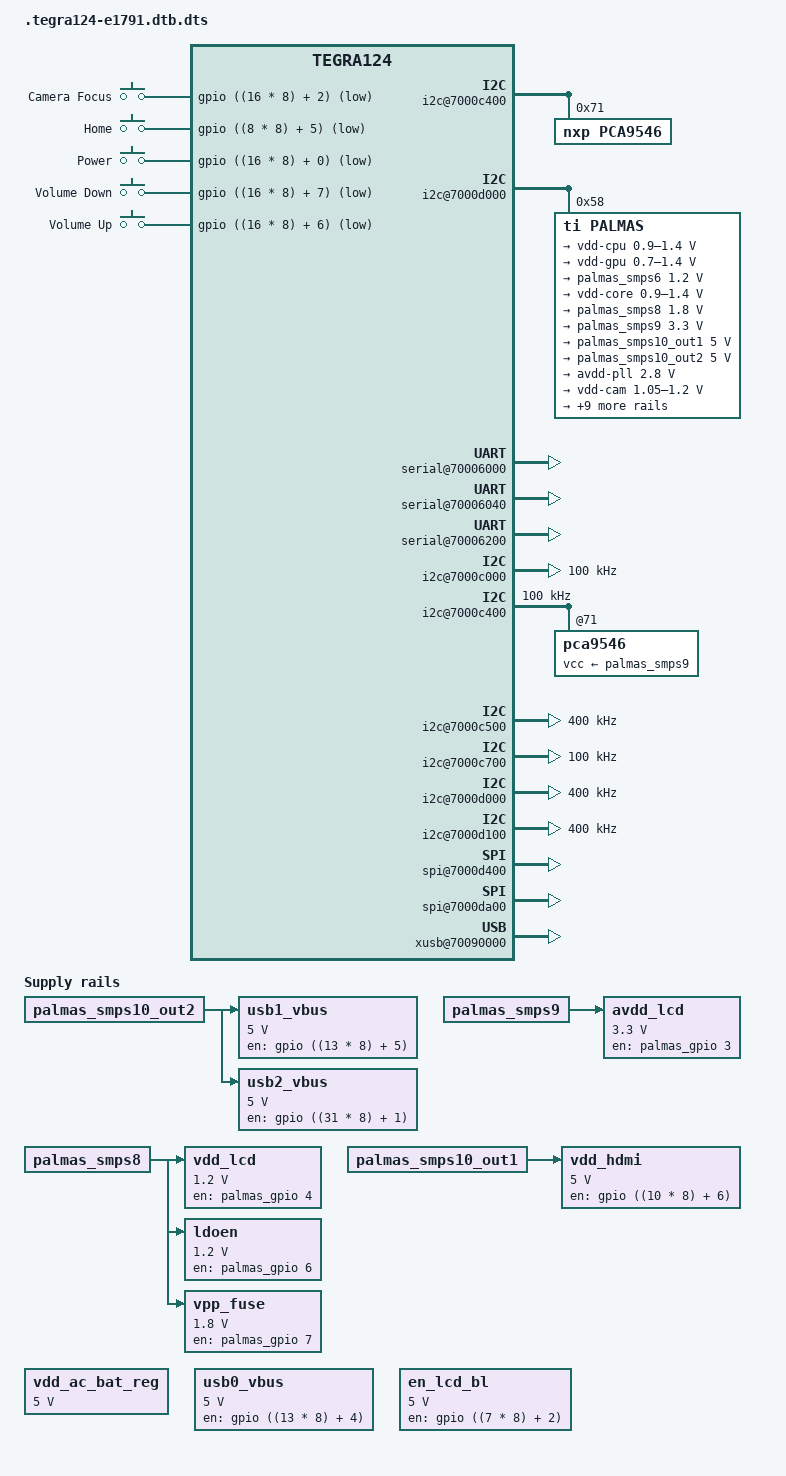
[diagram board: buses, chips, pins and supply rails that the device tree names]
# 1 "arch/arm/boot/dts/tegra124-e1791.dts"
# 1 "<built-in>"
# 1 "<command-line>"
# 1 "arch/arm/boot/dts/tegra124-e1791.dts"
/dts-v1/;

# 1 "arch/arm/boot/dts/tegra124.dtsi" 1
# 1 "/home/leeymcj/linuxrk-tk1/arch/arm/boot/dts/include/dt-bindings/gpio/tegra-gpio.h" 1
# 13 "/home/leeymcj/linuxrk-tk1/arch/arm/boot/dts/include/dt-bindings/gpio/tegra-gpio.h"
# 1 "/home/leeymcj/linuxrk-tk1/arch/arm/boot/dts/include/dt-bindings/gpio/gpio.h" 1
# 14 "/home/leeymcj/linuxrk-tk1/arch/arm/boot/dts/include/dt-bindings/gpio/tegra-gpio.h" 2
# 2 "arch/arm/boot/dts/tegra124.dtsi" 2
# 1 "/home/leeymcj/linuxrk-tk1/arch/arm/boot/dts/include/dt-bindings/input/input.h" 1
# 3 "arch/arm/boot/dts/tegra124.dtsi" 2
# 1 "/home/leeymcj/linuxrk-tk1/arch/arm/boot/dts/include/dt-bindings/interrupt-controller/arm-gic.h" 1







# 1 "/home/leeymcj/linuxrk-tk1/arch/arm/boot/dts/include/dt-bindings/interrupt-controller/irq.h" 1
# 9 "/home/leeymcj/linuxrk-tk1/arch/arm/boot/dts/include/dt-bindings/interrupt-controller/arm-gic.h" 2
# 4 "arch/arm/boot/dts/tegra124.dtsi" 2

/include/ "tegra124-soc.dtsi"

# 1 "arch/arm/boot/dts/skeleton.dtsi" 1






/ {
 #address-cells = <1>;
 #size-cells = <1>;
 chosen { };
 aliases { };
 memory { device_type = "memory"; reg = <0 0>; };
};
# 8 "arch/arm/boot/dts/tegra124.dtsi" 2

/ {
 compatible = "nvidia,tegra124";
 interrupt-parent = <&intc>;
 #address-cells = <1>;
 #size-cells = <1>;

 intc: interrupt-controller@50041000 {
  compatible = "arm,cortex-a15-gic";
  interrupt-controller;
  #interrupt-cells = <3>;
  reg = <0x50041000 0x1000>,
        <0x50042000 0x0100>;
 };

 lic: interrupt-controller@60004000 {
  compatible = "nvidia,tegra-gic";
  interrupt-controller;
  reg = <0x60004000 0x40>,
        <0x60004100 0x40>,
        <0x60004200 0x40>,
        <0x60004300 0x40>,
        <0x60004400 0x40>;
        };

 timer {
  compatible = "arm,armv7-timer";
  interrupts = <1 13 0xf04
         1 14 0xf04>;
 };
};
# 4 "arch/arm/boot/dts/tegra124-e1791.dts" 2
# 1 "arch/arm/boot/dts/tegra124-platforms/tegra124-e1780-powermon.dtsi" 1
# 18 "arch/arm/boot/dts/tegra124-platforms/tegra124-e1780-powermon.dtsi"
/ {
 aliases {
  i2c6 = &pca9546_i2c0;
  i2c7 = &pca9546_i2c1;
  i2c8 = &pca9546_i2c2;
  i2c9 = &pca9546_i2c3;
 };

 i2c@7000c400 {
  pca9546@71 {
   compatible = "nxp,pca9546";
   reg = <0x71>;
   #address-cells = <1>;
   #size-cells = <0>;
   pca9546_i2c0: i2c@0 {
    reg = <0>;
    i2c-mux,deselect-on-exit;
   };

   pca9546_i2c1: i2c@1 {
    reg = <1>;
    i2c-mux,deselect-on-exit;
   };

   pca9546_i2c2: i2c@2 {
    reg = <2>;
    i2c-mux,deselect-on-exit;
   };

   pca9546_i2c3: i2c@3 {
    reg = <3>;
    i2c-mux,deselect-on-exit;
   };
  };
 };
};
# 5 "arch/arm/boot/dts/tegra124-e1791.dts" 2
# 1 "arch/arm/boot/dts/tegra124-platforms/tegra124-e1791-e1736-pmic.dtsi" 1
/ {
 i2c@7000d000 {
  palmas: tps65913 {
   compatible = "ti,palmas";
   reg = <0x58>;
   interrupts = <0 86 0>;

   #interrupt-cells = <2>;
   interrupt-controller;

   palmas_gpio: gpio {
    compatible = "ti,palmas-gpio";
    gpio-controller;
    #gpio-cells = <2>;
   };

   rtc {
    compatible = "ti,palmas-rtc";
    interrupt-parent = <&palmas>;
    interrupts = <8 0>;
   };

   pinmux {
    compatible = "ti,tps65913-pinctrl";
    pinctrl-names = "default";
    pinctrl-0 = <&palmas_default>;

    palmas_default: pinmux {
     powergood {
      pins = "powergood";
      function = "powergood";
     };

     vac {
      pins = "vac";
      function = "vac";
     };

     pin_gpio0 {
      pins = "gpio0";
      function = "id";
      bias-pull-up;
     };

     pin_gpio1 {
      pins = "gpio1";
      function = "vbus_det";
     };

     pin_gpio6 {
      pins = "gpio2", "gpio3", "gpio4", "gpio6", "gpio7";
      function = "gpio";
     };

     pin_gpio5 {
      pins = "gpio5";
      function = "clk32kgaudio";
     };
    };
   };

   extcon {
    compatible = "ti,palmas-usb";
    extcon-name = "palmas-extcon";
    ti,wakeup;
    ti,enable-id-detection;
    ti,enable-vbus-detection;
   };

   power_pm {
    compatible = "ti,palmas-pm";
    system-pmic-power-off;
    system-pmic-power-reset;
   };

   gpadc {
    compatible = "ti,palmas-gpadc";
    interrupt-parent = <&palmas>;
    interrupts = <18 0
        16 0
        17 0>;
    iio_map {
     ch1 {
      ti,adc-channel-number = <1>;
      ti,adc-consumer-device = "generic-adc-thermal.0";
      ti,adc-consumer-channel ="battery-temp-channel";
     };

     ch6 {
      ti,adc-channel-number = <6>;
      ti,adc-consumer-device = "palmas-battery";
      ti,adc-consumer-channel ="vbat_channel";
     };
    };
   };

   clock {
    compatible = "ti,palmas-clk";

    clk32k_kg {
     ti,clock-boot-enable;
    };

    clk32k_kg_audio {
     ti,clock-boot-enable;
    };
   };

   pmic {
    compatible = "ti,tps65913-pmic", "ti,palmas-pmic";
    ldo1-in-supply = <&palmas_smps6>;
    ldo2-in-supply = <&palmas_smps6>;
    ldo5-in-supply = <&palmas_smps8>;
    ldo6-in-supply = <&palmas_smps9>;
    ldo7-in-supply = <&palmas_smps9>;
    ldo9-in-supply = <&palmas_smps9>;
    ldoln-in-supply = <&palmas_smps10_out2>;

    regulators {
     smps123 {
      regulator-name = "vdd-cpu";
      regulator-min-microvolt = <900000>;
      regulator-max-microvolt = <1400000>;
      regulator-always-on;
      regulator-boot-on;
      ti,roof-floor = <1>;

      consumers {
       c1 {
        regulator-consumer-supply = "vdd_cpu";
       };
      };
     };

     smps45 {
      regulator-name = "vdd-gpu";
      regulator-min-microvolt = <700000>;
      regulator-max-microvolt = <1400000>;
      regulator-init-microvolt = <1000000>;
      regulator-always-on;
      regulator-boot-on;

      consumers {
       c1 {
        regulator-consumer-supply = "vdd_gpu";
       };
       c2 {
        regulator-consumer-supply = "vdd_gpu_simon";
       };
      };
     };

     palmas_smps6: smps6 {
      regulator-name = "vddio-ddr";
      regulator-min-microvolt = <1200000>;
      regulator-max-microvolt = <1200000>;
      regulator-always-on;
      regulator-boot-on;

      consumers {
       c1 {
        regulator-consumer-supply = "vddio_ddr";
       };
       c2 {
        regulator-consumer-supply = "vddio_ddr_mclk";
       };
       c3 {
        regulator-consumer-supply = "vddio_ddr3";
       };
       c4 {
        regulator-consumer-supply = "vcore1_ddr3";
       };
      };
     };

     smps7 {
      regulator-name = "vdd-core";
      regulator-min-microvolt = <900000>;
      regulator-max-microvolt = <1400000>;
      regulator-always-on;
      regulator-boot-on;
      ti,roof-floor = <3>;
      consumers {
       c1 {
        regulator-consumer-supply = "vdd_core";
       };
      };
     };

     palmas_smps8: smps8 {
      regulator-name = "vdd-1v8";
      regulator-min-microvolt = <1800000>;
      regulator-max-microvolt = <1800000>;
      regulator-always-on;
      regulator-boot-on;

      consumers {
       c1 {
        regulator-consumer-supply = "dbvdd";
        regulator-consumer-device = "tegra-snd-rt5639.0";
       };
       c2 {
        regulator-consumer-supply = "dbvdd";
        regulator-consumer-device = "tegra-snd-rt5645.0";
       };
       c3 {
        regulator-consumer-supply = "avdd";
        regulator-consumer-device = "tegra-snd-rt5639.0";
       };
       c4 {
        regulator-consumer-supply = "avdd";
        regulator-consumer-device = "tegra-snd-rt5645.0";
       };
       c5 {
        regulator-consumer-supply = "dmicvdd";
        regulator-consumer-device = "tegra-snd-rt5639.0";
       };
       c6 {
        regulator-consumer-supply = "dmicvdd";
        regulator-consumer-device = "tegra-snd-rt5645.0";
       };
       c7 {
        regulator-consumer-supply = "avdd_osc";
       };
       c8 {
        regulator-consumer-supply = "vddio_sys";
       };
       c9 {
        regulator-consumer-supply = "vddio_sys_2";
       };
       c10 {
        regulator-consumer-supply = "pwrdet_nand";
       };
       c11 {
        regulator-consumer-supply = "vddio_sdmmc";
        regulator-consumer-device = "sdhci-tegra.0";
       };
       c12 {
        regulator-consumer-supply = "pwrdet_sdmmc1";
       };
       c13 {
        regulator-consumer-supply = "vddio_sdmmc";
        regulator-consumer-device = "sdhci-tegra.3";
       };
       c14 {
        regulator-consumer-supply = "pwrdet_sdmmc4";
       };
       c15 {
        regulator-consumer-supply = "avdd_pll_utmip";
        regulator-consumer-device = "tegra-udc.0";
       };
       c16 {
        regulator-consumer-supply = "avdd_pll_utmip";
        regulator-consumer-device = "tegra-ehci.0";
       };
       c17 {
        regulator-consumer-supply = "avdd_pll_utmip";
        regulator-consumer-device = "tegra-ehci.1";
       };
       c18 {
        regulator-consumer-supply = "avdd_pll_utmip";
        regulator-consumer-device = "tegra-ehci.2";
       };
       c19 {
        regulator-consumer-supply = "avdd_pll_utmip";
        regulator-consumer-device = "tegra-xhci";
       };
       c20 {
        regulator-consumer-supply = "vddio_audio";
       };
       c21 {
        regulator-consumer-supply = "pwrdet_audio";
       };
       c22 {
        regulator-consumer-supply = "vddio_uart";
       };
       c23 {
        regulator-consumer-supply = "pwrdet_uart";
       };
       c24 {
        regulator-consumer-supply = "vddio_bb";
       };
       c25 {
        regulator-consumer-supply = "pwrdet_bb";
       };
       c26 {
        regulator-consumer-supply = "vdd_dtv";
       };
       c27 {
        regulator-consumer-supply = "vdd_1v8_eeprom";
       };
       c28 {
        regulator-consumer-supply = "vddio_cam";
        regulator-consumer-device = "tegra_camera";
       };
       c29 {
        regulator-consumer-supply = "vddio_cam";
        regulator-consumer-device = "vi";
       };
       c30 {
        regulator-consumer-supply = "pwrdet_cam";
       };
       c31 {
        regulator-consumer-supply = "dvdd";
        regulator-consumer-device = "spi0.0";
       };
       c32 {
        regulator-consumer-supply = "vlogic";
        regulator-consumer-device = "0-0069";
       };
       c33 {
        regulator-consumer-supply = "vid";
        regulator-consumer-device = "0-000d";
       };
       c34 {
        regulator-consumer-supply = "vddio";
        regulator-consumer-device = "0-0077";
       };
       c35 {
        regulator-consumer-supply = "dvdd_lcd";
       };
       c36 {
        regulator-consumer-supply = "vdd_lcd_1v8_s";
       };
      };
     };

     palmas_smps9: smps9 {
      regulator-name = "vdd-snsr";
      regulator-min-microvolt = <3300000>;
      regulator-max-microvolt = <3300000>;

      consumers {
       c1 {
        regulator-consumer-supply = "vdd_snsr";
       };
       c2 {
        regulator-consumer-supply = "vddio_sd_slot";
        regulator-consumer-device = "sdhci-tegra.3";
       };
       c3 {
        regulator-consumer-supply = "vddio_sd_slot";
        regulator-consumer-device = "sdhci-tegra.2";
       };
       c4 {
        regulator-consumer-supply = "vdd_3v3_gps";
       };
       c5 {
        regulator-consumer-supply = "vdd_3v3_nfc";
       };
       c6 {
        regulator-consumer-supply = "vdd";
        regulator-consumer-device = "0-0069";
       };
       c7 {
        regulator-consumer-supply = "vdd";
        regulator-consumer-device = "0-000d";
       };
       c8 {
        regulator-consumer-supply = "vdd";
        regulator-consumer-device = "0-0077";
       };
       c9 {
        regulator-consumer-supply = "vdd";
        regulator-consumer-device = "1-004c";
       };
       c10 {
        regulator-consumer-supply = "vdd";
        regulator-consumer-device = "1-004d";
       };

      };
     };

     palmas_smps10_out1: smps10_out1 {
      regulator-name = "vdd-out1-5v0";
      regulator-min-microvolt = <5000000>;
      regulator-max-microvolt = <5000000>;
     };

     palmas_smps10_out2: smps10_out2 {
      regulator-name = "vdd-out2-5v0";
      regulator-min-microvolt = <5000000>;
      regulator-max-microvolt = <5000000>;

      consumers {
       c1 {
        regulator-consumer-supply = "vdd_5v0_mdm";
       };
       c2 {
        regulator-consumer-supply = "vdd_5v0_snsr";
       };
       c3 {
        regulator-consumer-supply = "vdd_5v0_dis";
       };
       c4 {
        regulator-consumer-supply = "spkvdd";
        regulator-consumer-device = "tegra-snd-rt5639.0";
       };
       c5 {
        regulator-consumer-supply = "spkvdd";
        regulator-consumer-device = "tegra-snd-rt5645.0";
       };
       c6 {
        regulator-consumer-supply = "avddio_pex";
        regulator-consumer-device = "tegra-pcie";
       };
       c7 {
        regulator-consumer-supply = "dvddio_pex";
        regulator-consumer-device = "tegra-pcie";
       };
       c8 {
        regulator-consumer-supply = "avddio_usb";
        regulator-consumer-device = "tegra-xhci";
       };

      };
     };

     ldo1 {
      regulator-name = "avdd-pll";
      regulator-min-microvolt = <2800000>;
      regulator-max-microvolt = <2800000>;
      regulator-always-on;
      regulator-boot-on;
      ti,roof-floor = <3>;

      consumers {
       c1 {
        regulator-consumer-supply = "avdd_pll_m";
       };
       c2 {
        regulator-consumer-supply = "avdd_pll_ap_c2_c3";
       };
       c3 {
        regulator-consumer-supply = "avdd_pll_cud2dpd";
       };
       c4 {
        regulator-consumer-supply = "avdd_pll_c4";
       };
       c5 {
        regulator-consumer-supply = "avdd_lvds0_io";
       };
       c6 {
        regulator-consumer-supply = "vddio_ddr_hs";
       };
       c7 {
        regulator-consumer-supply = "avdd_pll_erefe";
       };
       c8 {
        regulator-consumer-supply = "avdd_pll_x";
       };
       c9 {
        regulator-consumer-supply = "avdd_pll_cg";
       };
       c10 {
        regulator-consumer-supply = "avdd_pex_pll";
        regulator-consumer-device = "tegra-pcie";
       };
       c11 {
        regulator-consumer-supply = "avdd_hdmi_pll";
        regulator-consumer-device = "tegradc.1";
       };

      };
     };

     ldo2 {
      regulator-name = "vdd-cam";
      regulator-min-microvolt = <1050000>;
      regulator-max-microvolt = <1200000>;

      consumers {
       c1 {
        regulator-consumer-supply = "vdd_cam_1v1_cam";
       };
       c2 {
        regulator-consumer-supply = "imx135_reg2";
       };
       c3 {
        regulator-consumer-supply = "vdd_1v2_cam";
       };
       c4 {
        regulator-consumer-supply = "vdig";
        regulator-consumer-device = "2-0010";

       };
       c5 {
        regulator-consumer-supply = "dvdd";
        regulator-consumer-device = "2-0010";
       };
       c6 {
        regulator-consumer-supply = "vdig";
        regulator-consumer-device = "2-0036";
       };

      };
     };

     ldo3 {
      regulator-name = "vdd-touch";
      regulator-min-microvolt = <3300000>;
      regulator-max-microvolt = <3300000>;

      consumers {
       c1 {
        regulator-consumer-supply = "avdd";
        regulator-consumer-device = "spi0.0";
       };

      };
     };

     ldo4 {
      regulator-name = "avdd-cam";
      regulator-min-microvolt = <2700000>;
      regulator-max-microvolt = <2700000>;

      consumers {
       c1 {
        regulator-consumer-supply = "vdd_2v7_hv";
       };
       c2 {
        regulator-consumer-supply = "avdd_cam1_cam";
       };
       c3 {
        regulator-consumer-supply = "avdd_cam2_cam";
       };
       c4 {
        regulator-consumer-supply = "avdd_cam3_cam";
       };
       c5 {
        regulator-consumer-supply = "vana";
        regulator-consumer-device = "2-0010";
       };
       c6 {
        regulator-consumer-supply = "avdd";
        regulator-consumer-device = "2-0010";
       };
       c7 {
        regulator-consumer-supply = "vana";
        regulator-consumer-device = "2-0036";
       };
       c8 {
        regulator-consumer-supply = "avdd_ov5693";
        regulator-consumer-device = "2-0010";
       };
      };
     };

     ldo5 {
      regulator-name = "avdd-dsi-csi";
      regulator-min-microvolt = <1200000>;
      regulator-max-microvolt = <1200000>;

      consumers {
       c1 {
        regulator-consumer-supply = "vddio_hsic";
        regulator-consumer-device = "tegra-ehci.1";
       };
       c2 {
        regulator-consumer-supply = "vddio_hsic";
        regulator-consumer-device = "tegra-ehci.2";
       };
       c3 {
        regulator-consumer-supply = "vddio_hsic";
        regulator-consumer-device = "tegra-xhci";
       };
       c4 {
        regulator-consumer-supply = "avdd_dsi_csi";
        regulator-consumer-device = "tegradc.0";

       };
       c5 {
        regulator-consumer-supply = "avdd_dsi_csi";
        regulator-consumer-device = "tegradc.1";
       };
       c6 {
        regulator-consumer-supply = "avdd_dsi_csi";
        regulator-consumer-device = "vi";
       };
       c7 {
        regulator-consumer-supply = "pwrdet_mipi";
       };
       c8 {
        regulator-consumer-supply = "avdd_hsic_com";
       };
       c9 {
        regulator-consumer-supply = "avdd_hsic_mdm";

       };
       c10 {
        regulator-consumer-supply = "vdd_lcd_bl";
       };

      };
     };

     ldo6 {
      regulator-name = "vdd-cam-af";
      regulator-min-microvolt = <1800000>;
      regulator-max-microvolt = <1800000>;

      consumers {
       c1 {
        regulator-consumer-supply = "vdd_cam1_1v8_cam";
       };
       c2 {
        regulator-consumer-supply = "vdd_cam2_1v8_cam";
       };
       c3 {
        regulator-consumer-supply = "vif";
        regulator-consumer-device = "2-0010";
       };
       c4 {
        regulator-consumer-supply = "dovdd";
        regulator-consumer-device = "2-0010";

       };
       c5 {
        regulator-consumer-supply = "vif2";
        regulator-consumer-device = "2-0021";
       };
       c6 {
        regulator-consumer-supply = "vif";
        regulator-consumer-device = "2-0036";
       };
       c7 {
        regulator-consumer-supply = "vdd_i2c";
        regulator-consumer-device = "2-000c";

       };
       c8 {
        regulator-consumer-supply = "vi2c";
        regulator-consumer-device = "2-0030";
       };
      };
     };

     ldo7 {
      regulator-name = "avdd-cam-af";
      regulator-min-microvolt = <2700000>;
      regulator-max-microvolt = <2700000>;

      consumers {
       c1 {
        regulator-consumer-supply = "avdd_af1_cam";
       };
       c2 {
        regulator-consumer-supply = "imx135_reg1";
       };
       c3 {
        regulator-consumer-supply = "vana";
        regulator-consumer-device = "2-0021";
       };
       c4 {
        regulator-consumer-supply = "vdd";
        regulator-consumer-device = "2-000c";
       };
      };
     };

     ldo8 {
      regulator-name = "vdd-rtc";
      regulator-min-microvolt = <900000>;
      regulator-max-microvolt = <900000>;
      regulator-always-on;
      regulator-boot-on;

      consumers {
       c1 {
        regulator-consumer-supply = "vdd_rtc";
       };
      };
     };

     ldo9 {
      regulator-name = "vddio-sdmmc-2";
      regulator-min-microvolt = <1800000>;
      regulator-max-microvolt = <3300000>;

      consumers {
       c1 {
        regulator-consumer-supply = "vddio_sdmmc";
        regulator-consumer-device = "sdhci-tegra.2";
       };
       c2 {
        regulator-consumer-supply = "pwrdet_sdmmc3";
       };
      };
     };

     ldoln {
      regulator-name = "vddio-hv";
      regulator-min-microvolt = <3300000>;
      regulator-max-microvolt = <3300000>;

      consumers {
       c1 {
        regulator-consumer-supply = "vddio_hv";
        regulator-consumer-device = "tegradc.1";
       };
       c2 {
        regulator-consumer-supply = "avdd_hdmi";
        regulator-consumer-device = "tegradc.1";

       };
       c3 {
        regulator-consumer-supply = "pwrdet_hv";
       };
       c4 {
        regulator-consumer-supply = "vddio_pex_ctl";
        regulator-consumer-device = "tegra-pcie";
       };
      };
     };

     ldousb {
      regulator-name = "avdd-usb";
      regulator-min-microvolt = <3300000>;
      regulator-max-microvolt = <3300000>;
      regulator-always-on;
      regulator-boot-on;

      consumers {
       c1 {
        regulator-consumer-supply = "pwrdet_pex_ctl";
       };
       c2 {
        regulator-consumer-supply = "avdd_usb";
        regulator-consumer-device = "tegra-udc.0";

       };
       c3 {
        regulator-consumer-supply = "avdd_usb";
        regulator-consumer-device = "tegra-ehci.0";
       };
       c4 {
        regulator-consumer-supply = "avdd_usb";
        regulator-consumer-device = "tegra-ehci.1";
       };
       c5 {
        regulator-consumer-supply = "avdd_usb";
        regulator-consumer-device = "tegra-ehci.2";
       };
       c6 {
        regulator-consumer-supply = "hvdd_usb";
        regulator-consumer-device = "tegra-xhci";

       };
       c7 {
        regulator-consumer-supply = "hvdd_pex";
        regulator-consumer-device = "tegra-pcie";
       };
       c8 {
        regulator-consumer-supply = "hvdd_pex_pll_e";
        regulator-consumer-device = "tegra-pcie";
       };

      };
     };
    };
   };
  };
 };
};
# 6 "arch/arm/boot/dts/tegra124-e1791.dts" 2
# 1 "arch/arm/boot/dts/tegra124-platforms/tegra124-tn8-e1736-fixed.dtsi" 1


/ {
 regulators {
  compatible = "simple-bus";
  #address-cells = <1>;
  #size-cells = <0>;

  vdd_ac_bat_reg: regulator@0 {
   compatible = "regulator-fixed";
   reg = <0>;
   regulator-name = "vdd_ac_bat";
   regulator-min-microvolt = <5000000>;
   regulator-max-microvolt = <5000000>;
   regulator-always-on;

   consumers {
    c1 {
     regulator-consumer-supply = "vdd_sys_bl";
    };
   };
  };

  usb0_vbus: regulator@1 {
   compatible = "regulator-fixed-sync";
   reg = <1>;
   regulator-name = "usb0-vbus";
   regulator-min-microvolt = <5000000>;
   regulator-max-microvolt = <5000000>;
   gpio = <&gpio ((13 * 8) + 4) 0>;
   enable-active-high;
   gpio-open-drain;

   consumers {
    c1 {
     regulator-consumer-supply = "usb_vbus0";
     regulator-consumer-device = "tegra-xhci";
    };
   };
  };

  usb1_vbus: regulator@2 {
   compatible = "regulator-fixed-sync";
   reg = <2>;
   regulator-name = "usb1-vbus";
   regulator-min-microvolt = <5000000>;
   regulator-max-microvolt = <5000000>;
   enable-active-high;
   gpio = <&gpio ((13 * 8) + 5) 0>;
   gpio-open-drain;
   vin-supply = <&palmas_smps10_out2>;

   consumers {
    c1 {
     regulator-consumer-supply = "usb_vbus";
     regulator-consumer-device = "tegra-ehci.1";
    };
    c2 {
     regulator-consumer-supply = "usb_vbus1";
     regulator-consumer-device = "tegra-xhci";
    };
   };
  };

  usb2_vbus: regulator@3 {
   compatible = "regulator-fixed-sync";
   reg = <3>;
   regulator-name = "usb2-vbus";
   regulator-min-microvolt = <5000000>;
   regulator-max-microvolt = <5000000>;
   enable-active-high;
   gpio = <&gpio ((31 * 8) + 1) 0>;
   gpio-open-drain;
   vin-supply = <&palmas_smps10_out2>;

   consumers {
    c1 {
     regulator-consumer-supply = "usb_vbus";
     regulator-consumer-device = "tegra-ehci.2";
    };
    c2 {
     regulator-consumer-supply = "usb_vbus2";
     regulator-consumer-device = "tegra-xhci";
    };
   };
  };

  avdd_lcd: regulator@4 {
   compatible = "regulator-fixed-sync";
   reg = <4>;
   regulator-name = "avdd-lcd";
   regulator-min-microvolt = <3300000>;
   regulator-max-microvolt = <3300000>;
   gpio = <&palmas_gpio 3 0>;
   enable-active-high;
   vin-supply = <&palmas_smps9>;

   consumers {
    c1 {
     regulator-consumer-supply = "avdd_lcd";
    };
   };
  };

  vdd_lcd: regulator@5 {
   compatible = "regulator-fixed-sync";
   reg = <5>;
   regulator-name = "vdd-lcd";
   regulator-min-microvolt = <1200000>;
   regulator-max-microvolt = <1200000>;
   enable-active-high;
   gpio = <&palmas_gpio 4 0>;
   vin-supply = <&palmas_smps8>;

   consumers {
    c1 {
     regulator-consumer-supply = "vdd_lcd_1v2_s";
    };
   };
  };

  ldoen: regulator@6 {
   compatible = "regulator-fixed-sync";
   reg = <6>;
   regulator-name = "ldoen";
   regulator-min-microvolt = <1200000>;
   regulator-max-microvolt = <1200000>;
   enable-active-high;
   gpio = <&palmas_gpio 6 0>;
   vin-supply = <&palmas_smps8>;

   consumers {
    c1 {
     regulator-consumer-supply = "ldoen";
     regulator-consumer-device = "tegra-snd-rt5639";
    };
   };
  };

  vpp_fuse: regulator@7 {
   compatible = "regulator-fixed-sync";
   reg = <7>;
   regulator-name = "vpp-fuse";
   regulator-min-microvolt = <1800000>;
   regulator-max-microvolt = <1800000>;
   enable-active-high;
   gpio = <&palmas_gpio 7 0>;
   vin-supply = <&palmas_smps8>;

   consumers {
    c1 {
     regulator-consumer-supply = "vpp_fuse";
    };
   };
  };

  en_lcd_bl: regulator@8 {
   compatible = "regulator-fixed-sync";
   reg = <8>;
   regulator-name = "en-lcd-bl";
   regulator-min-microvolt = <5000000>;
   regulator-max-microvolt = <5000000>;
   enable-active-high;
   gpio = <&gpio ((7 * 8) + 2) 0>;

   consumers {
    c1 {
     regulator-consumer-supply = "vdd_lcd_bl_en";
    };
   };
  };

  vdd_hdmi: regulator@9 {
   compatible = "regulator-fixed-sync";
   reg = <9>;
   regulator-name = "vdd-hdmi";
   regulator-min-microvolt = <5000000>;
   regulator-max-microvolt = <5000000>;
   enable-active-high;
   gpio = <&gpio ((10 * 8) + 6) 0>;
   vin-supply = <&palmas_smps10_out1>;

   consumers {
    c1 {
     regulator-consumer-supply = "vdd_hdmi_5v0";
     regulator-consumer-device = "tegradc.1";
    };
   };
  };
 };
};
# 7 "arch/arm/boot/dts/tegra124-e1791.dts" 2
# 1 "arch/arm/boot/dts/tegra124-platforms/tegra124-e1780-gpio-default.dtsi" 1


/ {
 gpio: gpio@6000d000 {
  gpio-init-names = "default";
  gpio-init-0 = <&gpio_default>;

  gpio_default: default {
   gpio-input = < ((2 * 8) + 7)
     ((6 * 8) + 2)
     ((6 * 8) + 3)
     ((7 * 8) + 4)
     ((8 * 8) + 5)
     ((8 * 8) + 6)
     ((9 * 8) + 0)
     ((10 * 8) + 2)
     ((10 * 8) + 3)
     ((13 * 8) + 7)
     ((14 * 8) + 0)
     ((14 * 8) + 2)
     ((14 * 8) + 3)
     ((14 * 8) + 5)
     ((14 * 8) + 7)
     ((16 * 8) + 0)
     ((16 * 8) + 1)
     ((16 * 8) + 2)
     ((16 * 8) + 5)
     ((16 * 8) + 6)
     ((16 * 8) + 7)
     ((17 * 8) + 4)
     ((18 * 8) + 0)
     ((18 * 8) + 1)
     ((20 * 8) + 1)
     ((20 * 8) + 2)
     ((20 * 8) + 5)
     ((20 * 8) + 6)
     ((21 * 8) + 0)
     ((21 * 8) + 1)
     ((21 * 8) + 3)
     ((22 * 8) + 2)
     ((22 * 8) + 3)
     ((23 * 8) + 3)
     ((23 * 8) + 5)
     ((23 * 8) + 6)
     ((28 * 8) + 1)
     ((28 * 8) + 2)>;
   gpio-output-low = <((6 * 8) + 0)
     ((6 * 8) + 1)
     ((7 * 8) + 3)
     ((7 * 8) + 5)
     ((8 * 8) + 0)
     ((8 * 8) + 2)
     ((8 * 8) + 4)
     ((10 * 8) + 1)
     ((10 * 8) + 5)
     ((10 * 8) + 6)
     ((14 * 8) + 6)
     ((17 * 8) + 0)
     ((17 * 8) + 1)
     ((17 * 8) + 2)
     ((17 * 8) + 5)
     ((18 * 8) + 3)
     ((18 * 8) + 4)
     ((18 * 8) + 6)
     ((20 * 8) + 0)
     ((20 * 8) + 3)
     ((20 * 8) + 4)
     ((23 * 8) + 1)
     ((23 * 8) + 4)
     ((23 * 8) + 7)
     ((27 * 8) + 3)
     ((27 * 8) + 5)
     ((27 * 8) + 6)
     ((27 * 8) + 7)
     ((28 * 8) + 5)
     ((30 * 8) + 1)>;
   gpio-output-high = <((7 * 8) + 2)
     ((10 * 8) + 4)
     ((18 * 8) + 5)
     ((23 * 8) + 2)>;
  };
 };
};
# 8 "arch/arm/boot/dts/tegra124-e1791.dts" 2
# 1 "arch/arm/boot/dts/tegra124-platforms/tegra124-e1780-pinmux.dtsi" 1
# 1 "/home/leeymcj/linuxrk-tk1/arch/arm/boot/dts/include/dt-bindings/pinctrl/pinctrl-tegra.h" 1
# 2 "arch/arm/boot/dts/tegra124-platforms/tegra124-e1780-pinmux.dtsi" 2

/ {
 pinmux: pinmux {
  pinctrl-names = "default", "drive", "unused";
  pinctrl-0 = <&pinmux_default>;
  pinctrl-1 = <&drive_default>;
  pinctrl-2 = <&pinmux_unused_lowpower>;

  pinmux_default: common {
   dap_mclk1_pw4 {
    nvidia,pins = "dap_mclk1_pw4";
    nvidia,function = "extperiph1";
    nvidia,enable-input = <0>;
    nvidia,pull = <0>;
    nvidia,tristate = <0>;
   };

   dap1_din_pn1 {
    nvidia,pins = "dap1_din_pn1";
    nvidia,function = "i2s0";
    nvidia,enable-input = <1>;
    nvidia,pull = <0>;
    nvidia,tristate = <1>;
   };

   dap1_dout_pn2 {
    nvidia,pins = "dap1_dout_pn2";
    nvidia,function = "i2s0";
    nvidia,enable-input = <0>;
    nvidia,pull = <0>;
    nvidia,tristate = <1>;
   };

   dap1_fs_pn0 {
    nvidia,pins = "dap1_fs_pn0";
    nvidia,function = "i2s0";
    nvidia,enable-input = <1>;
    nvidia,pull = <0>;
    nvidia,tristate = <1>;
   };

   dap1_sclk_pn3 {
    nvidia,pins = "dap1_sclk_pn3";
    nvidia,function = "i2s0";
    nvidia,enable-input = <1>;
    nvidia,pull = <0>;
    nvidia,tristate = <1>;
   };

   dap2_din_pa4 {
    nvidia,pins = "dap2_din_pa4";
    nvidia,function = "i2s1";
    nvidia,enable-input = <1>;
    nvidia,pull = <0>;
    nvidia,tristate = <1>;
   };

   dap2_dout_pa5 {
    nvidia,pins = "dap2_dout_pa5";
    nvidia,function = "i2s1";
    nvidia,enable-input = <0>;
    nvidia,pull = <0>;
    nvidia,tristate = <1>;
   };

   dap2_fs_pa2 {
    nvidia,pins = "dap2_fs_pa2";
    nvidia,function = "i2s1";
    nvidia,enable-input = <1>;
    nvidia,pull = <0>;
    nvidia,tristate = <1>;
   };

   dap2_sclk_pa3 {
    nvidia,pins = "dap2_sclk_pa3";
    nvidia,function = "i2s1";
    nvidia,enable-input = <1>;
    nvidia,pull = <0>;
    nvidia,tristate = <1>;
   };

   dvfs_pwm_px0 {
    nvidia,pins = "dvfs_pwm_px0";
    nvidia,function = "cldvfs";
    nvidia,enable-input = <0>;
    nvidia,pull = <0>;
    nvidia,tristate = <1>;
   };

   dvfs_clk_px2 {
    nvidia,pins = "dvfs_clk_px2";
    nvidia,function = "cldvfs";
    nvidia,enable-input = <0>;
    nvidia,pull = <0>;
    nvidia,tristate = <0>;
   };

   ulpi_clk_py0 {
    nvidia,pins = "ulpi_clk_py0";
    nvidia,function = "spi1";
    nvidia,enable-input = <1>;
    nvidia,pull = <2>;
    nvidia,tristate = <0>;
   };

   ulpi_dir_py1 {
    nvidia,pins = "ulpi_dir_py1";
    nvidia,function = "spi1";
    nvidia,enable-input = <1>;
    nvidia,pull = <2>;
    nvidia,tristate = <0>;
   };

   ulpi_nxt_py2 {
    nvidia,pins = "ulpi_nxt_py2";
    nvidia,function = "spi1";
    nvidia,enable-input = <1>;
    nvidia,pull = <2>;
    nvidia,tristate = <0>;
   };

   ulpi_stp_py3 {
    nvidia,pins = "ulpi_stp_py3";
    nvidia,function = "spi1";
    nvidia,enable-input = <1>;
    nvidia,pull = <2>;
    nvidia,tristate = <0>;
   };

   cam_i2c_scl_pbb1 {
    nvidia,pins = "cam_i2c_scl_pbb1";
    nvidia,function = "i2c3";
    nvidia,enable-input = <1>;
    nvidia,pull = <0>;
    nvidia,tristate = <0>;
    nvidia,lock = <0>;
    nvidia,open-drain = <1>;
   };

   cam_i2c_sda_pbb2 {
    nvidia,pins = "cam_i2c_sda_pbb2";
    nvidia,function = "i2c3";
    nvidia,enable-input = <1>;
    nvidia,pull = <0>;
    nvidia,tristate = <0>;
    nvidia,lock = <0>;
    nvidia,open-drain = <1>;
   };

   cam_mclk_pcc0 {
    nvidia,pins = "cam_mclk_pcc0";
    nvidia,function = "vi_alt3";
    nvidia,enable-input = <0>;
    nvidia,pull = <0>;
    nvidia,tristate = <0>;
   };

   pbb0 {
    nvidia,pins = "pbb0";
    nvidia,function = "vimclk2_alt";
    nvidia,enable-input = <0>;
    nvidia,pull = <0>;
    nvidia,tristate = <0>;
   };

   pbb4 {
    nvidia,pins = "pbb4";
    nvidia,function = "vgp4";
    nvidia,enable-input = <0>;
    nvidia,pull = <0>;
    nvidia,tristate = <0>;
   };

   gen2_i2c_scl_pt5 {
    nvidia,pins = "gen2_i2c_scl_pt5";
    nvidia,function = "i2c2";
    nvidia,enable-input = <1>;
    nvidia,pull = <0>;
    nvidia,tristate = <0>;
    nvidia,lock = <0>;
    nvidia,open-drain = <1>;
   };

   gen2_i2c_sda_pt6 {
    nvidia,pins = "gen2_i2c_sda_pt6";
    nvidia,function = "i2c2";
    nvidia,enable-input = <1>;
    nvidia,pull = <0>;
    nvidia,tristate = <0>;
    nvidia,lock = <0>;
    nvidia,open-drain = <1>;
   };

   pj7 {
    nvidia,pins = "pj7";
    nvidia,function = "uartd";
    nvidia,enable-input = <0>;
    nvidia,pull = <0>;
    nvidia,tristate = <0>;
   };

   pb0 {
    nvidia,pins = "pb0";
    nvidia,function = "uartd";
    nvidia,enable-input = <1>;
    nvidia,pull = <2>;
    nvidia,tristate = <0>;
   };

   pb1 {
    nvidia,pins = "pb1";
    nvidia,function = "uartd";
    nvidia,enable-input = <1>;
    nvidia,pull = <2>;
    nvidia,tristate = <0>;
   };

   pk7 {
    nvidia,pins = "pk7";
    nvidia,function = "uartd";
    nvidia,enable-input = <0>;
    nvidia,pull = <0>;
    nvidia,tristate = <0>;
   };

   pg4 {
    nvidia,pins = "pg4";
    nvidia,function = "spi4";
    nvidia,enable-input = <0>;
    nvidia,pull = <0>;
    nvidia,tristate = <0>;
   };

   pg5 {
    nvidia,pins = "pg5";
    nvidia,function = "spi4";
    nvidia,enable-input = <0>;
    nvidia,pull = <0>;
    nvidia,tristate = <0>;
   };

   pg6 {
    nvidia,pins = "pg6";
    nvidia,function = "spi4";
    nvidia,enable-input = <0>;
    nvidia,pull = <0>;
    nvidia,tristate = <0>;
   };

   pg7 {
    nvidia,pins = "pg7";
    nvidia,function = "spi4";
    nvidia,enable-input = <1>;
    nvidia,pull = <0>;
    nvidia,tristate = <0>;
   };

   pi3 {
    nvidia,pins = "pi3";
    nvidia,function = "spi4";
    nvidia,enable-input = <0>;
    nvidia,pull = <0>;
    nvidia,tristate = <0>;
   };

   ph0 {
    nvidia,pins = "ph0";
    nvidia,function = "dtv";
    nvidia,enable-input = <1>;
    nvidia,pull = <1>;
    nvidia,tristate = <1>;
   };

   ph1 {
    nvidia,pins = "ph1";
    nvidia,function = "pwm1";
    nvidia,enable-input = <0>;
    nvidia,pull = <0>;
    nvidia,tristate = <0>;
   };

   pk0 {
    nvidia,pins = "pk0";
    nvidia,function = "soc";
    nvidia,enable-input = <1>;
    nvidia,pull = <2>;
    nvidia,tristate = <0>;
   };

   pj2 {
    nvidia,pins = "pj2";
    nvidia,function = "soc";
    nvidia,enable-input = <1>;
    nvidia,pull = <2>;
    nvidia,tristate = <0>;
   };

   kb_row15_ps7 {
    nvidia,pins = "kb_row15_ps7";
    nvidia,function = "soc";
    nvidia,enable-input = <1>;
    nvidia,pull = <2>;
    nvidia,tristate = <0>;
   };

   clk_32k_out_pa0 {
    nvidia,pins = "clk_32k_out_pa0";
    nvidia,function = "soc";
    nvidia,enable-input = <1>;
    nvidia,pull = <2>;
    nvidia,tristate = <0>;
   };

   clk2_out_pw5 {
    nvidia,pins = "clk2_out_pw5";
    nvidia,function = "extperiph2";
    nvidia,enable-input = <0>;
    nvidia,pull = <0>;
    nvidia,tristate = <0>;
   };

   sdmmc1_clk_pz0 {
    nvidia,pins = "sdmmc1_clk_pz0";
    nvidia,function = "sdmmc1";
    nvidia,enable-input = <1>;
    nvidia,pull = <0>;
    nvidia,tristate = <0>;
   };

   sdmmc1_cmd_pz1 {
    nvidia,pins = "sdmmc1_cmd_pz1";
    nvidia,function = "sdmmc1";
    nvidia,enable-input = <1>;
    nvidia,pull = <2>;
    nvidia,tristate = <0>;
   };

   sdmmc1_dat0_py7 {
    nvidia,pins = "sdmmc1_dat0_py7";
    nvidia,function = "sdmmc1";
    nvidia,enable-input = <1>;
    nvidia,pull = <2>;
    nvidia,tristate = <0>;
   };

   sdmmc1_dat1_py6 {
    nvidia,pins = "sdmmc1_dat1_py6";
    nvidia,function = "sdmmc1";
    nvidia,enable-input = <1>;
    nvidia,pull = <2>;
    nvidia,tristate = <0>;
   };

   sdmmc1_dat2_py5 {
    nvidia,pins = "sdmmc1_dat2_py5";
    nvidia,function = "sdmmc1";
    nvidia,enable-input = <1>;
    nvidia,pull = <2>;
    nvidia,tristate = <0>;
   };

   sdmmc1_dat3_py4 {
    nvidia,pins = "sdmmc1_dat3_py4";
    nvidia,function = "sdmmc1";
    nvidia,enable-input = <1>;
    nvidia,pull = <2>;
    nvidia,tristate = <0>;
   };

   sdmmc3_clk_pa6 {
    nvidia,pins = "sdmmc3_clk_pa6";
    nvidia,function = "sdmmc3";
    nvidia,enable-input = <1>;
    nvidia,pull = <0>;
    nvidia,tristate = <0>;
   };

   sdmmc3_cmd_pa7 {
    nvidia,pins = "sdmmc3_cmd_pa7";
    nvidia,function = "sdmmc3";
    nvidia,enable-input = <1>;
    nvidia,pull = <2>;
    nvidia,tristate = <0>;
   };

   sdmmc3_dat0_pb7 {
    nvidia,pins = "sdmmc3_dat0_pb7";
    nvidia,function = "sdmmc3";
    nvidia,enable-input = <1>;
    nvidia,pull = <2>;
    nvidia,tristate = <0>;
   };

   sdmmc3_dat1_pb6 {
    nvidia,pins = "sdmmc3_dat1_pb6";
    nvidia,function = "sdmmc3";
    nvidia,enable-input = <1>;
    nvidia,pull = <2>;
    nvidia,tristate = <0>;
   };

   sdmmc3_dat2_pb5 {
    nvidia,pins = "sdmmc3_dat2_pb5";
    nvidia,function = "sdmmc3";
    nvidia,enable-input = <1>;
    nvidia,pull = <2>;
    nvidia,tristate = <0>;
   };

   sdmmc3_dat3_pb4 {
    nvidia,pins = "sdmmc3_dat3_pb4";
    nvidia,function = "sdmmc3";
    nvidia,enable-input = <1>;
    nvidia,pull = <2>;
    nvidia,tristate = <0>;
   };

   sdmmc3_clk_lb_out_pee4 {
    nvidia,pins = "sdmmc3_clk_lb_out_pee4";
    nvidia,function = "sdmmc3";
    nvidia,enable-input = <1>;
    nvidia,pull = <2>;
    nvidia,tristate = <0>;
   };

   sdmmc3_clk_lb_in_pee5 {
    nvidia,pins = "sdmmc3_clk_lb_in_pee5";
    nvidia,function = "sdmmc3";
    nvidia,enable-input = <1>;
    nvidia,pull = <2>;
    nvidia,tristate = <0>;
   };

   kb_col4_pq4 {
    nvidia,pins = "kb_col4_pq4";
    nvidia,function = "sdmmc3";
    nvidia,enable-input = <1>;
    nvidia,pull = <2>;
    nvidia,tristate = <0>;
   };

   sdmmc3_cd_n_pv2 {
    nvidia,pins = "sdmmc3_cd_n_pv2";
    nvidia,function = "sdmmc3";
    nvidia,enable-input = <1>;
    nvidia,pull = <2>;
    nvidia,tristate = <0>;
   };

   sdmmc4_clk_pcc4 {
    nvidia,pins = "sdmmc4_clk_pcc4";
    nvidia,function = "sdmmc4";
    nvidia,enable-input = <1>;
    nvidia,pull = <0>;
    nvidia,tristate = <0>;
   };

   sdmmc4_cmd_pt7 {
    nvidia,pins = "sdmmc4_cmd_pt7";
    nvidia,function = "sdmmc4";
    nvidia,enable-input = <1>;
    nvidia,pull = <2>;
    nvidia,tristate = <0>;
   };

   sdmmc4_dat0_paa0 {
    nvidia,pins = "sdmmc4_dat0_paa0";
    nvidia,function = "sdmmc4";
    nvidia,enable-input = <1>;
    nvidia,pull = <2>;
    nvidia,tristate = <0>;
   };

   sdmmc4_dat1_paa1 {
    nvidia,pins = "sdmmc4_dat1_paa1";
    nvidia,function = "sdmmc4";
    nvidia,enable-input = <1>;
    nvidia,pull = <2>;
    nvidia,tristate = <0>;
   };

   sdmmc4_dat2_paa2 {
    nvidia,pins = "sdmmc4_dat2_paa2";
    nvidia,function = "sdmmc4";
    nvidia,enable-input = <1>;
    nvidia,pull = <2>;
    nvidia,tristate = <0>;
   };

   sdmmc4_dat3_paa3 {
    nvidia,pins = "sdmmc4_dat3_paa3";
    nvidia,function = "sdmmc4";
    nvidia,enable-input = <1>;
    nvidia,pull = <2>;
    nvidia,tristate = <0>;
   };

   sdmmc4_dat4_paa4 {
    nvidia,pins = "sdmmc4_dat4_paa4";
    nvidia,function = "sdmmc4";
    nvidia,enable-input = <1>;
    nvidia,pull = <2>;
    nvidia,tristate = <0>;
   };

   sdmmc4_dat5_paa5 {
    nvidia,pins = "sdmmc4_dat5_paa5";
    nvidia,function = "sdmmc4";
    nvidia,enable-input = <1>;
    nvidia,pull = <2>;
    nvidia,tristate = <0>;
   };

   sdmmc4_dat6_paa6 {
    nvidia,pins = "sdmmc4_dat6_paa6";
    nvidia,function = "sdmmc4";
    nvidia,enable-input = <1>;
    nvidia,pull = <2>;
    nvidia,tristate = <0>;
   };

   sdmmc4_dat7_paa7 {
    nvidia,pins = "sdmmc4_dat7_paa7";
    nvidia,function = "sdmmc4";
    nvidia,enable-input = <1>;
    nvidia,pull = <2>;
    nvidia,tristate = <0>;
   };

   kb_row10_ps2 {
    nvidia,pins = "kb_row10_ps2";
    nvidia,function = "uarta";
    nvidia,enable-input = <1>;
    nvidia,pull = <2>;
    nvidia,tristate = <0>;
   };

   kb_row9_ps1 {
    nvidia,pins = "kb_row9_ps1";
    nvidia,function = "uarta";
    nvidia,enable-input = <0>;
    nvidia,pull = <0>;
    nvidia,tristate = <0>;
   };

   kb_row3_pr3 {
    nvidia,pins = "kb_row3_pr3";
    nvidia,function = "sys";
    nvidia,enable-input = <0>;
    nvidia,pull = <0>;
    nvidia,tristate = <0>;
   };

   kb_row6_pr6 {
    nvidia,pins = "kb_row6_pr6";
    nvidia,function = "displaya_alt";
    nvidia,enable-input = <1>;
    nvidia,pull = <0>;
    nvidia,tristate = <0>;
   };

   pwr_i2c_scl_pz6 {
    nvidia,pins = "pwr_i2c_scl_pz6";
    nvidia,function = "i2cpwr";
    nvidia,enable-input = <1>;
    nvidia,pull = <0>;
    nvidia,tristate = <0>;
    nvidia,open-drain = <1>;
   };

   pwr_i2c_sda_pz7 {
    nvidia,pins = "pwr_i2c_sda_pz7";
    nvidia,function = "i2cpwr";
    nvidia,enable-input = <1>;
    nvidia,pull = <0>;
    nvidia,tristate = <0>;
    nvidia,open-drain = <1>;
   };

   jtag_rtck {
    nvidia,pins = "jtag_rtck";
    nvidia,function = "rtck";
    nvidia,enable-input = <0>;
    nvidia,pull = <2>;
    nvidia,tristate = <0>;
   };

   clk_32k_in {
    nvidia,pins = "clk_32k_in";
    nvidia,function = "clk";
    nvidia,enable-input = <1>;
    nvidia,pull = <0>;
    nvidia,tristate = <0>;
   };

   core_pwr_req {
    nvidia,pins = "core_pwr_req";
    nvidia,function = "pwron";
    nvidia,enable-input = <0>;
    nvidia,pull = <0>;
    nvidia,tristate = <0>;
   };

   cpu_pwr_req {
    nvidia,pins = "cpu_pwr_req";
    nvidia,function = "cpu";
    nvidia,enable-input = <0>;
    nvidia,pull = <0>;
    nvidia,tristate = <0>;
   };

   pwr_int_n {
    nvidia,pins = "pwr_int_n";
    nvidia,function = "pmi";
    nvidia,enable-input = <1>;
    nvidia,pull = <2>;
    nvidia,tristate = <0>;
   };

   reset_out_n {
    nvidia,pins = "reset_out_n";
    nvidia,function = "reset_out_n";
    nvidia,enable-input = <0>;
    nvidia,pull = <0>;
    nvidia,tristate = <0>;
   };

   clk3_out_pee0 {
    nvidia,pins = "clk3_out_pee0";
    nvidia,function = "extperiph3";
    nvidia,enable-input = <0>;
    nvidia,pull = <0>;
    nvidia,tristate = <0>;
   };

   dp_hpd_pff0 {
    nvidia,pins = "dp_hpd_pff0";
    nvidia,function = "dp";
    nvidia,enable-input = <1>;
    nvidia,pull = <0>;
    nvidia,tristate = <0>;
   };

   dap4_din_pp5 {
    nvidia,pins = "dap4_din_pp5";
    nvidia,function = "i2s3";
    nvidia,enable-input = <1>;
    nvidia,pull = <0>;
    nvidia,tristate = <1>;
   };

   dap4_dout_pp6 {
    nvidia,pins = "dap4_dout_pp6";
    nvidia,function = "i2s3";
    nvidia,enable-input = <0>;
    nvidia,pull = <0>;
    nvidia,tristate = <1>;
   };

   dap4_fs_pp4 {
    nvidia,pins = "dap4_fs_pp4";
    nvidia,function = "i2s3";
    nvidia,enable-input = <1>;
    nvidia,pull = <0>;
    nvidia,tristate = <1>;
   };

   dap4_sclk_pp7 {
    nvidia,pins = "dap4_sclk_pp7";
    nvidia,function = "i2s3";
    nvidia,enable-input = <1>;
    nvidia,pull = <0>;
    nvidia,tristate = <1>;
   };

   gen1_i2c_sda_pc5 {
    nvidia,pins = "gen1_i2c_sda_pc5";
    nvidia,function = "i2c1";
    nvidia,enable-input = <1>;
    nvidia,pull = <0>;
    nvidia,tristate = <0>;
    nvidia,lock = <0>;
    nvidia,open-drain = <0>;
   };

   gen1_i2c_scl_pc4 {
    nvidia,pins = "gen1_i2c_scl_pc4";
    nvidia,function = "i2c1";
    nvidia,enable-input = <1>;
    nvidia,pull = <0>;
    nvidia,tristate = <0>;
    nvidia,lock = <0>;
    nvidia,open-drain = <0>;
   };

   uart2_cts_n_pj5 {
    nvidia,pins = "uart2_cts_n_pj5";
    nvidia,function = "uartb";
    nvidia,enable-input = <1>;
    nvidia,pull = <0>;
    nvidia,tristate = <0>;
   };

   uart2_rts_n_pj6 {
    nvidia,pins = "uart2_rts_n_pj6";
    nvidia,function = "uartb";
    nvidia,enable-input = <0>;
    nvidia,pull = <0>;
    nvidia,tristate = <0>;
   };

   uart2_rxd_pc3 {
    nvidia,pins = "uart2_rxd_pc3";
    nvidia,function = "irda";
    nvidia,enable-input = <1>;
    nvidia,pull = <0>;
    nvidia,tristate = <0>;
   };

   uart2_txd_pc2 {
    nvidia,pins = "uart2_txd_pc2";
    nvidia,function = "irda";
    nvidia,enable-input = <0>;
    nvidia,pull = <0>;
    nvidia,tristate = <0>;
   };

   uart3_cts_n_pa1 {
    nvidia,pins = "uart3_cts_n_pa1";
    nvidia,function = "uartc";
    nvidia,enable-input = <1>;
    nvidia,pull = <0>;
    nvidia,tristate = <0>;
   };

   uart3_rts_n_pc0 {
    nvidia,pins = "uart3_rts_n_pc0";
    nvidia,function = "uartc";
    nvidia,enable-input = <0>;
    nvidia,pull = <0>;
    nvidia,tristate = <0>;
   };

   uart3_rxd_pw7 {
    nvidia,pins = "uart3_rxd_pw7";
    nvidia,function = "uartc";
    nvidia,enable-input = <1>;
    nvidia,pull = <0>;
    nvidia,tristate = <0>;
   };

   uart3_txd_pw6 {
    nvidia,pins = "uart3_txd_pw6";
    nvidia,function = "uartc";
    nvidia,enable-input = <0>;
    nvidia,pull = <0>;
    nvidia,tristate = <0>;
   };

   hdmi_cec_pee3 {
    nvidia,pins = "hdmi_cec_pee3";
    nvidia,function = "cec";
    nvidia,enable-input = <1>;
    nvidia,pull = <0>;
    nvidia,tristate = <0>;
    nvidia,open-drain = <1>;
   };

   ddc_scl_pv4 {
    nvidia,pins = "ddc_scl_pv4";
    nvidia,function = "i2c4";
    nvidia,enable-input = <1>;
    nvidia,pull = <0>;
    nvidia,tristate = <0>;
   };

   ddc_sda_pv5 {
    nvidia,pins = "ddc_sda_pv5";
    nvidia,function = "i2c4";
    nvidia,enable-input = <1>;
    nvidia,pull = <0>;
    nvidia,tristate = <0>;
   };

   usb_vbus_en0_pn4 {
    nvidia,pins = "usb_vbus_en0_pn4";
    nvidia,function = "usb";
    nvidia,enable-input = <1>;
    nvidia,pull = <2>;
    nvidia,tristate = <0>;
    nvidia,lock = <0>;
    nvidia,open-drain = <0>;
   };

   usb_vbus_en1_pn5 {
    nvidia,pins = "usb_vbus_en1_pn5";
    nvidia,function = "usb";
    nvidia,enable-input = <1>;
    nvidia,pull = <2>;
    nvidia,tristate = <0>;
    nvidia,lock = <0>;
    nvidia,open-drain = <0>;
   };

   usb_vbus_en2_pff1 {
    nvidia,pins = "usb_vbus_en2_pff1";
    nvidia,function = "usb";
    nvidia,enable-input = <1>;
    nvidia,pull = <2>;
    nvidia,tristate = <0>;
    nvidia,lock = <0>;
    nvidia,open-drain = <0>;
   };

   ph6 {
    nvidia,pins = "ph6";
    nvidia,function = "dtv";
    nvidia,enable-input = <1>;
    nvidia,pull = <1>;
    nvidia,tristate = <1>;
   };

   ph7 {
    nvidia,pins = "ph7";
    nvidia,function = "dtv";
    nvidia,enable-input = <1>;
    nvidia,pull = <1>;
    nvidia,tristate = <1>;
   };

   pi7 {
    nvidia,pins = "pi7";
    nvidia,function = "dtv";
    nvidia,enable-input = <1>;
    nvidia,pull = <1>;
    nvidia,tristate = <1>;
   };

   gpio_x4_aud_px4 {
    nvidia,pins = "gpio_x4_aud_px4";
    nvidia,function = "safe";
    nvidia,enable-input = <0>;
    nvidia,pull = <0>;
    nvidia,tristate = <0>;
   };

   gpio_x5_aud_px5 {
    nvidia,pins = "gpio_x5_aud_px5";
    nvidia,function = "safe";
    nvidia,enable-input = <1>;
    nvidia,pull = <2>;
    nvidia,tristate = <0>;
   };

   gpio_x6_aud_px6 {
    nvidia,pins = "gpio_x6_aud_px6";
    nvidia,function = "safe";
    nvidia,enable-input = <1>;
    nvidia,pull = <2>;
    nvidia,tristate = <0>;
   };

   gpio_x7_aud_px7 {
    nvidia,pins = "gpio_x7_aud_px7";
    nvidia,function = "safe";
    nvidia,enable-input = <0>;
    nvidia,pull = <0>;
    nvidia,tristate = <0>;
   };

   gpio_w2_aud_pw2 {
    nvidia,pins = "gpio_w2_aud_pw2";
    nvidia,function = "safe";
    nvidia,enable-input = <1>;
    nvidia,pull = <2>;
    nvidia,tristate = <0>;
   };

   gpio_w3_aud_pw3 {
    nvidia,pins = "gpio_w3_aud_pw3";
    nvidia,function = "safe";
    nvidia,enable-input = <1>;
    nvidia,pull = <2>;
    nvidia,tristate = <0>;
   };

   gpio_x1_aud_px1 {
    nvidia,pins = "gpio_x1_aud_px1";
    nvidia,function = "safe";
    nvidia,enable-input = <0>;
    nvidia,pull = <0>;
    nvidia,tristate = <0>;
   };

   gpio_x3_aud_px3 {
    nvidia,pins = "gpio_x3_aud_px3";
    nvidia,function = "safe";
    nvidia,enable-input = <1>;
    nvidia,pull = <2>;
    nvidia,tristate = <0>;
   };

   pv0 {
    nvidia,pins = "pv0";
    nvidia,function = "safe";
    nvidia,enable-input = <1>;
    nvidia,pull = <2>;
    nvidia,tristate = <0>;
   };

   pv1 {
    nvidia,pins = "pv1";
    nvidia,function = "safe";
    nvidia,enable-input = <1>;
    nvidia,pull = <2>;
    nvidia,tristate = <0>;
   };

   ulpi_data1_po2 {
    nvidia,pins = "ulpi_data1_po2";
    nvidia,function = "safe";
    nvidia,enable-input = <1>;
    nvidia,pull = <2>;
    nvidia,tristate = <0>;
   };

   ulpi_data2_po3 {
    nvidia,pins = "ulpi_data2_po3";
    nvidia,function = "safe";
    nvidia,enable-input = <1>;
    nvidia,pull = <2>;
    nvidia,tristate = <0>;
   };

   ulpi_data4_po5 {
    nvidia,pins = "ulpi_data4_po5";
    nvidia,function = "safe";
    nvidia,enable-input = <1>;
    nvidia,pull = <2>;
    nvidia,tristate = <0>;
   };

   ulpi_data5_po6 {
    nvidia,pins = "ulpi_data5_po6";
    nvidia,function = "safe";
    nvidia,enable-input = <0>;
    nvidia,pull = <0>;
    nvidia,tristate = <0>;
   };

   ulpi_data6_po7 {
    nvidia,pins = "ulpi_data6_po7";
    nvidia,function = "safe";
    nvidia,enable-input = <1>;
    nvidia,pull = <2>;
    nvidia,tristate = <0>;
   };

   ulpi_data7_po0 {
    nvidia,pins = "ulpi_data7_po0";
    nvidia,function = "safe";
    nvidia,enable-input = <1>;
    nvidia,pull = <2>;
    nvidia,tristate = <0>;
   };

   pbb3 {
    nvidia,pins = "pbb3";
    nvidia,function = "safe";
    nvidia,enable-input = <0>;
    nvidia,pull = <0>;
    nvidia,tristate = <0>;
   };

   pbb5 {
    nvidia,pins = "pbb5";
    nvidia,function = "safe";
    nvidia,enable-input = <0>;
    nvidia,pull = <0>;
    nvidia,tristate = <0>;
   };

   pbb6 {
    nvidia,pins = "pbb6";
    nvidia,function = "safe";
    nvidia,enable-input = <0>;
    nvidia,pull = <0>;
    nvidia,tristate = <0>;
   };

   pbb7 {
    nvidia,pins = "pbb7";
    nvidia,function = "safe";
    nvidia,enable-input = <0>;
    nvidia,pull = <0>;
    nvidia,tristate = <0>;
   };

   pcc1 {
    nvidia,pins = "pcc1";
    nvidia,function = "safe";
    nvidia,enable-input = <1>;
    nvidia,pull = <1>;
    nvidia,tristate = <0>;
   };

   pcc2 {
    nvidia,pins = "pcc2";
    nvidia,function = "safe";
    nvidia,enable-input = <1>;
    nvidia,pull = <1>;
    nvidia,tristate = <0>;
   };

   pg0 {
    nvidia,pins = "pg0";
    nvidia,function = "safe";
    nvidia,enable-input = <0>;
    nvidia,pull = <0>;
    nvidia,tristate = <0>;
   };

   pg1 {
    nvidia,pins = "pg1";
    nvidia,function = "safe";
    nvidia,enable-input = <0>;
    nvidia,pull = <0>;
    nvidia,tristate = <0>;
   };

   ph2 {
    nvidia,pins = "ph2";
    nvidia,function = "safe";
    nvidia,enable-input = <0>;
    nvidia,pull = <0>;
    nvidia,tristate = <0>;
   };

   ph3 {
    nvidia,pins = "ph3";
    nvidia,function = "safe";
    nvidia,enable-input = <0>;
    nvidia,pull = <0>;
    nvidia,tristate = <0>;
   };

   ph4 {
    nvidia,pins = "ph4";
    nvidia,function = "safe";
    nvidia,enable-input = <1>;
    nvidia,pull = <2>;
    nvidia,tristate = <0>;
   };

   ph5 {
    nvidia,pins = "ph5";
    nvidia,function = "safe";
    nvidia,enable-input = <0>;
    nvidia,pull = <0>;
    nvidia,tristate = <0>;
   };

   pg2 {
    nvidia,pins = "pg2";
    nvidia,function = "safe";
    nvidia,enable-input = <1>;
    nvidia,pull = <1>;
    nvidia,tristate = <0>;
   };

   pg3 {
    nvidia,pins = "pg3";
    nvidia,function = "safe";
    nvidia,enable-input = <1>;
    nvidia,pull = <1>;
    nvidia,tristate = <0>;
   };

   pk1 {
    nvidia,pins = "pk1";
    nvidia,function = "safe";
    nvidia,enable-input = <0>;
    nvidia,pull = <0>;
    nvidia,tristate = <0>;
   };

   pj0 {
    nvidia,pins = "pj0";
    nvidia,function = "safe";
    nvidia,enable-input = <1>;
    nvidia,pull = <2>;
    nvidia,tristate = <0>;
   };

   pk3 {
    nvidia,pins = "pk3";
    nvidia,function = "safe";
    nvidia,enable-input = <1>;
    nvidia,pull = <2>;
    nvidia,tristate = <0>;
   };

   pk4 {
    nvidia,pins = "pk4";
    nvidia,function = "safe";
    nvidia,enable-input = <0>;
    nvidia,pull = <0>;
    nvidia,tristate = <0>;
   };

   pk2 {
    nvidia,pins = "pk2";
    nvidia,function = "safe";
    nvidia,enable-input = <1>;
    nvidia,pull = <2>;
    nvidia,tristate = <0>;
   };

   pi6 {
    nvidia,pins = "pi6";
    nvidia,function = "safe";
    nvidia,enable-input = <1>;
    nvidia,pull = <2>;
    nvidia,tristate = <0>;
   };

   pi2 {
    nvidia,pins = "pi2";
    nvidia,function = "safe";
    nvidia,enable-input = <0>;
    nvidia,pull = <0>;
    nvidia,tristate = <0>;
   };

   pi5 {
    nvidia,pins = "pi5";
    nvidia,function = "safe";
    nvidia,enable-input = <1>;
    nvidia,pull = <2>;
    nvidia,tristate = <0>;
   };

   pi4 {
    nvidia,pins = "pi4";
    nvidia,function = "safe";
    nvidia,enable-input = <0>;
    nvidia,pull = <0>;
    nvidia,tristate = <0>;
   };

   pc7 {
    nvidia,pins = "pc7";
    nvidia,function = "safe";
    nvidia,enable-input = <1>;
    nvidia,pull = <2>;
    nvidia,tristate = <0>;
   };

   pi0 {
    nvidia,pins = "pi0";
    nvidia,function = "safe";
    nvidia,enable-input = <0>;
    nvidia,pull = <0>;
    nvidia,tristate = <0>;
   };

   clk2_req_pcc5 {
    nvidia,pins = "clk2_req_pcc5";
    nvidia,function = "safe";
    nvidia,enable-input = <0>;
    nvidia,pull = <0>;
    nvidia,tristate = <0>;
   };

   sdmmc1_wp_n_pv3 {
    nvidia,pins = "sdmmc1_wp_n_pv3";
    nvidia,function = "safe";
    nvidia,enable-input = <1>;
    nvidia,pull = <2>;
    nvidia,tristate = <0>;
   };

   kb_col0_pq0 {
    nvidia,pins = "kb_col0_pq0";
    nvidia,function = "safe";
    nvidia,enable-input = <1>;
    nvidia,pull = <2>;
    nvidia,tristate = <0>;
   };

   kb_col1_pq1 {
    nvidia,pins = "kb_col1_pq1";
    nvidia,function = "safe";
    nvidia,enable-input = <1>;
    nvidia,pull = <0>;
    nvidia,tristate = <0>;
   };

   kb_col2_pq2 {
    nvidia,pins = "kb_col2_pq2";
    nvidia,function = "safe";
    nvidia,enable-input = <1>;
    nvidia,pull = <2>;
    nvidia,tristate = <0>;
   };

   kb_col5_pq5 {
    nvidia,pins = "kb_col5_pq5";
    nvidia,function = "safe";
    nvidia,enable-input = <1>;
    nvidia,pull = <2>;
    nvidia,tristate = <0>;
   };

   kb_col6_pq6 {
    nvidia,pins = "kb_col6_pq6";
    nvidia,function = "safe";
    nvidia,enable-input = <1>;
    nvidia,pull = <2>;
    nvidia,tristate = <0>;
   };

   kb_col7_pq7 {
    nvidia,pins = "kb_col7_pq7";
    nvidia,function = "safe";
    nvidia,enable-input = <1>;
    nvidia,pull = <2>;
    nvidia,tristate = <0>;
   };

   kb_row0_pr0 {
    nvidia,pins = "kb_row0_pr0";
    nvidia,function = "safe";
    nvidia,enable-input = <0>;
    nvidia,pull = <0>;
    nvidia,tristate = <0>;
   };

   kb_row1_pr1 {
    nvidia,pins = "kb_row1_pr1";
    nvidia,function = "safe";
    nvidia,enable-input = <0>;
    nvidia,pull = <0>;
    nvidia,tristate = <0>;
   };

   kb_row11_ps3 {
    nvidia,pins = "kb_row11_ps3";
    nvidia,function = "safe";
    nvidia,enable-input = <0>;
    nvidia,pull = <0>;
    nvidia,tristate = <0>;
   };

   kb_row12_ps4 {
    nvidia,pins = "kb_row12_ps4";
    nvidia,function = "safe";
    nvidia,enable-input = <0>;
    nvidia,pull = <0>;
    nvidia,tristate = <0>;
   };

   kb_row13_ps5 {
    nvidia,pins = "kb_row13_ps5";
    nvidia,function = "safe";
    nvidia,enable-input = <0>;
    nvidia,pull = <0>;
    nvidia,tristate = <0>;
   };

   kb_row14_ps6 {
    nvidia,pins = "kb_row14_ps6";
    nvidia,function = "safe";
    nvidia,enable-input = <0>;
    nvidia,pull = <0>;
    nvidia,tristate = <0>;
   };

   kb_row2_pr2 {
    nvidia,pins = "kb_row2_pr2";
    nvidia,function = "safe";
    nvidia,enable-input = <0>;
    nvidia,pull = <0>;
    nvidia,tristate = <0>;
   };

   kb_row4_pr4 {
    nvidia,pins = "kb_row4_pr4";
    nvidia,function = "safe";
    nvidia,enable-input = <1>;
    nvidia,pull = <2>;
    nvidia,tristate = <0>;
   };

   kb_row5_pr5 {
    nvidia,pins = "kb_row5_pr5";
    nvidia,function = "safe";
    nvidia,enable-input = <0>;
    nvidia,pull = <0>;
    nvidia,tristate = <0>;
   };

   kb_row7_pr7 {
    nvidia,pins = "kb_row7_pr7";
    nvidia,function = "safe";
    nvidia,enable-input = <1>;
    nvidia,pull = <2>;
    nvidia,tristate = <0>;
   };

   kb_row8_ps0 {
    nvidia,pins = "kb_row8_ps0";
    nvidia,function = "safe";
    nvidia,enable-input = <1>;
    nvidia,pull = <2>;
    nvidia,tristate = <0>;
   };

   clk3_req_pee1 {
    nvidia,pins = "clk3_req_pee1";
    nvidia,function = "safe";
    nvidia,enable-input = <0>;
    nvidia,pull = <0>;
    nvidia,tristate = <0>;
   };

   pu0 {
    nvidia,pins = "pu0";
    nvidia,function = "safe";
    nvidia,enable-input = <0>;
    nvidia,pull = <0>;
    nvidia,tristate = <0>;
   };

   pu1 {
    nvidia,pins = "pu1";
    nvidia,function = "safe";
    nvidia,enable-input = <1>;
    nvidia,pull = <1>;
    nvidia,tristate = <0>;
   };

   pu2 {
    nvidia,pins = "pu2";
    nvidia,function = "safe";
    nvidia,enable-input = <1>;
    nvidia,pull = <1>;
    nvidia,tristate = <0>;
   };

   pu3 {
    nvidia,pins = "pu3";
    nvidia,function = "safe";
    nvidia,enable-input = <0>;
    nvidia,pull = <0>;
    nvidia,tristate = <0>;
   };

   pu4 {
    nvidia,pins = "pu4";
    nvidia,function = "safe";
    nvidia,enable-input = <0>;
    nvidia,pull = <0>;
    nvidia,tristate = <0>;
   };

   pu5 {
    nvidia,pins = "pu5";
    nvidia,function = "safe";
    nvidia,enable-input = <1>;
    nvidia,pull = <2>;
    nvidia,tristate = <0>;
   };

   pu6 {
    nvidia,pins = "pu6";
    nvidia,function = "safe";
    nvidia,enable-input = <1>;
    nvidia,pull = <2>;
    nvidia,tristate = <0>;
   };

   hdmi_int_pn7 {
    nvidia,pins = "hdmi_int_pn7";
    nvidia,function = "safe";
    nvidia,enable-input = <1>;
    nvidia,pull = <1>;
    nvidia,tristate = <0>;
   };

   spdif_out_pk5 {
    nvidia,pins = "spdif_out_pk5";
    nvidia,function = "safe";
    nvidia,enable-input = <0>;
    nvidia,pull = <0>;
    nvidia,tristate = <0>;
   };

   spdif_in_pk6 {
    nvidia,pins = "spdif_in_pk6";
    nvidia,function = "safe";
    nvidia,enable-input = <0>;
    nvidia,pull = <0>;
    nvidia,tristate = <0>;
   };
  };

  pinmux_unused_lowpower: unused_lowpower {
   dap_mclk1_req_pee2 {
    nvidia,pins = "dap_mclk1_req_pee2";
    nvidia,function = "safe";
    nvidia,enable-input = <0>;
    nvidia,pull = <1>;
    nvidia,tristate = <1>;
   };

   dap3_din_pp1 {
    nvidia,pins = "dap3_din_pp1";
    nvidia,function = "safe";
    nvidia,enable-input = <0>;
    nvidia,pull = <1>;
    nvidia,tristate = <1>;
   };

   dap3_dout_pp2 {
    nvidia,pins = "dap3_dout_pp2";
    nvidia,function = "safe";
    nvidia,enable-input = <0>;
    nvidia,pull = <1>;
    nvidia,tristate = <1>;
   };

   dap3_fs_pp0 {
    nvidia,pins = "dap3_fs_pp0";
    nvidia,function = "safe";
    nvidia,enable-input = <0>;
    nvidia,pull = <1>;
    nvidia,tristate = <1>;
   };

   dap3_sclk_pp3 {
    nvidia,pins = "dap3_sclk_pp3";
    nvidia,function = "safe";
    nvidia,enable-input = <0>;
    nvidia,pull = <1>;
    nvidia,tristate = <1>;
   };

   ulpi_data0_po1 {
    nvidia,pins = "ulpi_data0_po1";
    nvidia,function = "safe";
    nvidia,enable-input = <0>;
    nvidia,pull = <1>;
    nvidia,tristate = <1>;
   };

   ulpi_data3_po4 {
    nvidia,pins = "ulpi_data3_po4";
    nvidia,function = "safe";
    nvidia,enable-input = <0>;
    nvidia,pull = <1>;
    nvidia,tristate = <1>;
   };

   pi1 {
    nvidia,pins = "pi1";
    nvidia,function = "safe";
    nvidia,enable-input = <0>;
    nvidia,pull = <1>;
    nvidia,tristate = <1>;
   };

   pex_l0_clkreq_n_pdd2 {
    nvidia,pins = "pex_l0_clkreq_n_pdd2";
    nvidia,function = "safe";
    nvidia,enable-input = <0>;
    nvidia,pull = <1>;
    nvidia,tristate = <1>;
   };

   pex_l0_rst_n_pdd1 {
    nvidia,pins = "pex_l0_rst_n_pdd1";
    nvidia,function = "safe";
    nvidia,enable-input = <0>;
    nvidia,pull = <1>;
    nvidia,tristate = <1>;
   };

   pex_l1_clkreq_n_pdd6 {
    nvidia,pins = "pex_l1_clkreq_n_pdd6";
    nvidia,function = "safe";
    nvidia,enable-input = <0>;
    nvidia,pull = <1>;
    nvidia,tristate = <1>;
   };

   pex_l1_rst_n_pdd5 {
    nvidia,pins = "pex_l1_rst_n_pdd5";
    nvidia,function = "safe";
    nvidia,enable-input = <0>;
    nvidia,pull = <1>;
    nvidia,tristate = <1>;
   };

   pex_wake_n_pdd3 {
    nvidia,pins = "pex_wake_n_pdd3";
    nvidia,function = "safe";
    nvidia,enable-input = <0>;
    nvidia,pull = <1>;
    nvidia,tristate = <1>;
   };

   pff2 {
    nvidia,pins = "pff2";
    nvidia,function = "safe";
    nvidia,enable-input = <0>;
    nvidia,pull = <1>;
    nvidia,tristate = <1>;
   };

   kb_col3_pq3 {
    nvidia,pins = "kb_col3_pq3";
    nvidia,function = "safe";
    nvidia,enable-input = <0>;
    nvidia,pull = <1>;
    nvidia,tristate = <1>;
   };

   kb_row16_pt0 {
    nvidia,pins = "kb_row16_pt0";
    nvidia,function = "safe";
    nvidia,enable-input = <0>;
    nvidia,pull = <1>;
    nvidia,tristate = <1>;
   };

   kb_row17_pt1 {
    nvidia,pins = "kb_row17_pt1";
    nvidia,function = "safe";
    nvidia,enable-input = <0>;
    nvidia,pull = <1>;
    nvidia,tristate = <1>;
   };

   owr {
    nvidia,pins = "owr";
    nvidia,function = "safe";
    nvidia,enable-input = <0>;
    nvidia,pull = <1>;
    nvidia,tristate = <1>;
   };
  };

  drive_default: drive {
   drive_sdio1 {
    nvidia,pins = "drive_sdio1";
    nvidia,high-speed-mode = <1>;
    nvidia,schmitt = <0>;
    nvidia,low-power-mode = <3>;
    nvidia,pull-down-strength = <32>;
    nvidia,pull-up-strength = <42>;
    nvidia,slew-rate-rising = <0>;
    nvidia,slew-rate-falling = <0>;
   };

   drive_sdio3 {
    nvidia,pins = "drive_sdio3";
    nvidia,high-speed-mode = <1>;
    nvidia,schmitt = <0>;
    nvidia,low-power-mode = <3>;
    nvidia,pull-down-strength = <20>;
    nvidia,pull-up-strength = <36>;
    nvidia,slew-rate-rising = <0>;
    nvidia,slew-rate-falling = <0>;
   };

   drive_gma {
    nvidia,pins = "drive_gma";
    nvidia,high-speed-mode = <1>;
    nvidia,schmitt = <0>;
    nvidia,low-power-mode = <3>;
    nvidia,pull-down-strength = <1>;
    nvidia,pull-up-strength = <2>;
    nvidia,slew-rate-rising = <0>;
    nvidia,slew-rate-falling = <0>;
    nvidia,drive-type = <1>;
   };
  };
 };
};
# 9 "arch/arm/boot/dts/tegra124-e1791.dts" 2
# 1 "arch/arm/boot/dts/tegra124-platforms/tegra124-e1780-keys.dtsi" 1



/ {
 gpio-keys {
  compatible = "gpio-keys";

  camera_focus {
   label = "Camera Focus";
   gpios = <&gpio ((16 * 8) + 2) 1>;
   linux,code = <0x210>;
  };

  home {
   label = "Home";
   gpios = <&gpio ((8 * 8) + 5) 1>;
   linux,code = <102>;
  };

  power {
   label = "Power";
   gpios = <&gpio ((16 * 8) + 0) 1>;
   linux,code = <116>;
   gpio-key,wakeup;
  };

  volume_down {
   label = "Volume Down";
   gpios = <&gpio ((16 * 8) + 7) 1>;
   linux,code = <114>;
  };

  volume_up {
   label = "Volume Up";
   gpios = <&gpio ((16 * 8) + 6) 1>;
   linux,code = <115>;
  };
 };
};
# 10 "arch/arm/boot/dts/tegra124-e1791.dts" 2


/ {
 model = "NVIDIA Tegra124 Ardbeg";
 compatible = "nvidia,ardbeg", "nvidia,tegra124";
 nvidia,dtsfilename = "arch/arm/boot/dts/tegra124-e1791.dts";
 #address-cells = <1>;
 #size-cells = <1>;

 chosen {
  bootargs = "tegraid=40.0.0.00.00 vmalloc=256M video=tegrafb console=ttyS0,115200n8 earlyprintk";
  linux,initrd-start = <0x85000000>;
  linux,initrd-end = <0x851bc400>;
 };

        serial@70006000 {
                compatible = "nvidia,tegra114-hsuart";
                status = "okay";
        };

        serial@70006040 {
                compatible = "nvidia,tegra114-hsuart";
                status = "okay";
        };

        serial@70006200 {
                compatible = "nvidia,tegra114-hsuart";
                status = "okay";
        };

 memory@0x80000000 {
  device_type = "memory";
  reg = <0x80000000 0x80000000>;
 };

 i2c@7000c000 {
  status = "okay";
  clock-frequency = <100000>;
 };

 i2c@7000c400 {
  status = "okay";
  clock-frequency = <100000>;

  pca9546@71 {
   vcc-supply = <&palmas_smps9>;
  };
 };

 i2c@7000c500 {
  status = "okay";
  clock-frequency = <400000>;
 };

 i2c@7000c700 {
  status = "okay";
  clock-frequency = <100000>;
 };

 i2c@7000d000 {
  status = "okay";
  clock-frequency = <400000>;
  nvidia,bit-banging-xfer-after-shutdown;
 };

 i2c@7000d100 {
  status = "okay";
  clock-frequency = <400000>;
 };

 spi@7000d400 {
  status = "okay";
  spi-max-frequency = <25000000>;
 };

 spi@7000da00 {
  status = "okay";
  spi-max-frequency = <25000000>;
 };

 pmc {
  status = "okay";
  nvidia,invert-interrupt;
  nvidia,suspend-mode = <0>;
  nvidia,cpu-pwr-good-time = <500>;
  nvidia,cpu-pwr-off-time = <300>;
  nvidia,core-pwr-good-time = <3845 3845>;
  nvidia,core-pwr-off-time = <2000>;
  nvidia,core-power-req-active-high;
  nvidia,sys-clock-req-active-high;
 };

 stm8t143 {
  compatible = "stm,stm8t143";
  pout-gpio = <&gpio 190 0>;
  tout-gpio = <&gpio 112 0>;
 };

 xusb@70090000 {


  nvidia,gpio_ss1_sata = <0>;
  nvidia,portmap = <0x703>;
  nvidia,ss_portmap = <0x20>;
  nvidia,lane_owner = <6>;
  nvidia,ulpicap = <0>;
  nvidia,supply_utmi_vbuses = "usb_vbus0", "usb_vbus1", "usb_vbus2";
  nvidia,supply_s3p3v = "hvdd_usb";
  nvidia,supply_s1p8v = "avdd_pll_utmip";
  nvidia,supply_vddio_hsic = "vddio_hsic";
  nvidia,supply_s1p05v = "avddio_usb";
  status = "okay";
 };
};
